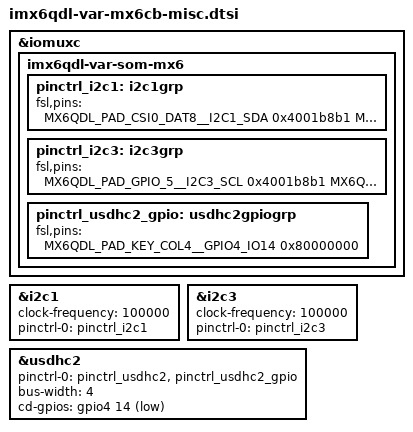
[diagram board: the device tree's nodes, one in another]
/*
 * Copyright (C) 2015-2024 Variscite Ltd.
 *
 * This program is free software; you can redistribute it and/or modify
 * it under the terms of the GNU General Public License version 2 as
 * published by the Free Software Foundation.
 *
 * Settings for VAR-MX6CustomBoard
 */

&iomuxc {
	imx6qdl-var-som-mx6 {
		pinctrl_i2c1: i2c1grp {
			fsl,pins = <
				MX6QDL_PAD_CSI0_DAT8__I2C1_SDA		0x4001b8b1
				MX6QDL_PAD_CSI0_DAT9__I2C1_SCL		0x4001b8b1
			>;
		};

		pinctrl_i2c3: i2c3grp {
			fsl,pins = <
				MX6QDL_PAD_GPIO_5__I2C3_SCL		0x4001b8b1
				MX6QDL_PAD_GPIO_16__I2C3_SDA		0x4001b8b1
			>;
		};

		pinctrl_usdhc2_gpio: usdhc2gpiogrp {
			fsl,pins = <
				/* SDMMC2 CD/WP */
				MX6QDL_PAD_KEY_COL4__GPIO4_IO14		0x80000000
			>;
		};
	};
};

&i2c1 {
	clock-frequency = <100000>;
	pinctrl-names = "default";
	pinctrl-0 = <&pinctrl_i2c1>;
	status = "okay";
};

&i2c3 {
	clock-frequency = <100000>;
	pinctrl-names = "default";
	pinctrl-0 = <&pinctrl_i2c3>;
	status = "okay";
};

&usdhc2 {	/* uSDHC2, MMC/SD card */
	pinctrl-names = "default";
	pinctrl-0 = <&pinctrl_usdhc2>, <&pinctrl_usdhc2_gpio>;
	bus-width = <4>;
	cd-gpios = <&gpio4 14 GPIO_ACTIVE_LOW>;
	status = "okay";
};
